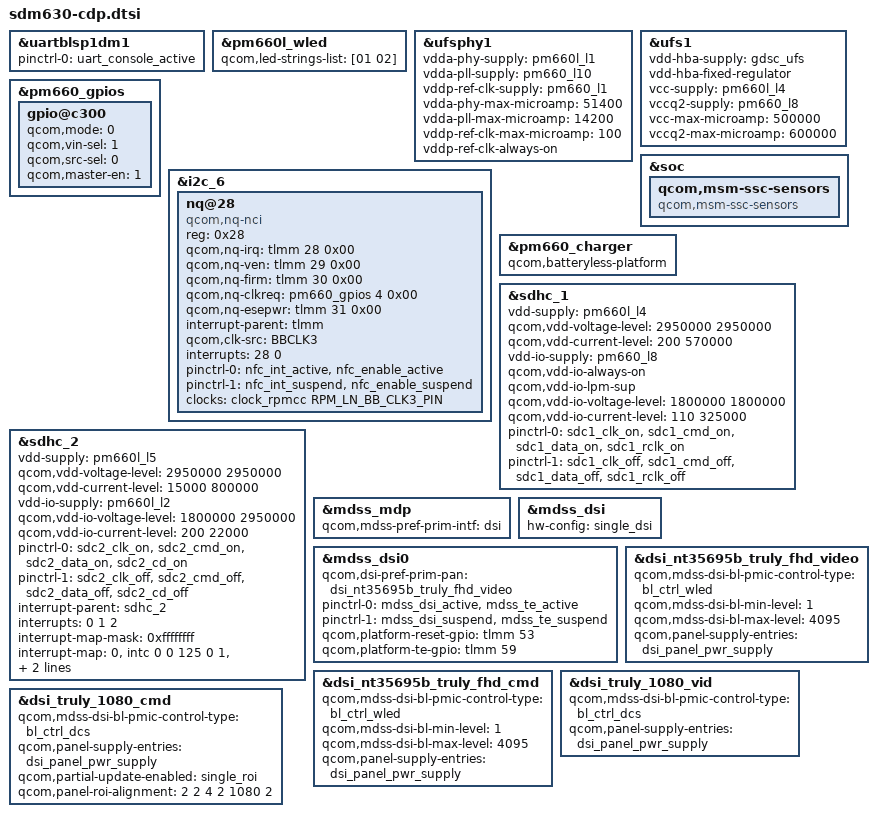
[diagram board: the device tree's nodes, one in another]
/* Copyright (c) 2017, The Linux Foundation. All rights reserved.
 *
 * This program is free software; you can redistribute it and/or modify
 * it under the terms of the GNU General Public License version 2 and
 * only version 2 as published by the Free Software Foundation.
 *
 * This program is distributed in the hope that it will be useful,
 * but WITHOUT ANY WARRANTY; without even the implied warranty of
 * MERCHANTABILITY or FITNESS FOR A PARTICULAR PURPOSE.  See the
 * GNU General Public License for more details.
 */

#include "sdm660-pinctrl.dtsi"
#include "sdm630-camera-sensor-cdp.dtsi"
/ {
};

&uartblsp1dm1 {
	status = "ok";
	pinctrl-names = "default";
	pinctrl-0 = <&uart_console_active>;
};

&pm660l_wled {
	qcom,led-strings-list = [01 02];
};

&ufsphy1 {
	vdda-phy-supply = <&pm660l_l1>;
	vdda-pll-supply = <&pm660_l10>;
	vddp-ref-clk-supply = <&pm660_l1>;
	vdda-phy-max-microamp = <51400>;
	vdda-pll-max-microamp = <14200>;
	vddp-ref-clk-max-microamp = <100>;
	vddp-ref-clk-always-on;
	status = "ok";
};

&ufs1 {
	vdd-hba-supply = <&gdsc_ufs>;
	vdd-hba-fixed-regulator;
	vcc-supply = <&pm660l_l4>;
	vccq2-supply = <&pm660_l8>;
	vcc-max-microamp = <500000>;
	vccq2-max-microamp = <600000>;
	status = "ok";
};

&pm660_gpios {
	/* GPIO 4 (NFC_CLK_REQ) */
	gpio@c300 {
		qcom,mode = <0>;
		qcom,vin-sel = <1>;
		qcom,src-sel = <0>;
		qcom,master-en = <1>;
		status = "okay";
	};
};

&i2c_6 { /* BLSP1 QUP6 (NFC) */
	status = "okay";
	nq@28 {
		compatible = "qcom,nq-nci";
		reg = <0x28>;
		qcom,nq-irq = <&tlmm 28 0x00>;
		qcom,nq-ven = <&tlmm 29 0x00>;
		qcom,nq-firm = <&tlmm 30 0x00>;
		qcom,nq-clkreq = <&pm660_gpios 4 0x00>;
		qcom,nq-esepwr = <&tlmm 31 0x00>;
		interrupt-parent = <&tlmm>;
		qcom,clk-src = "BBCLK3";
		interrupts = <28 0>;
		interrupt-names = "nfc_irq";
		pinctrl-names = "nfc_active", "nfc_suspend";
		pinctrl-0 = <&nfc_int_active &nfc_enable_active>;
		pinctrl-1 = <&nfc_int_suspend &nfc_enable_suspend>;
		clocks = <&clock_rpmcc RPM_LN_BB_CLK3_PIN>;
		clock-names = "ref_clk";
	};
};
&soc {
	qcom,msm-ssc-sensors {
		compatible = "qcom,msm-ssc-sensors";
	};
};

&pm660_charger {
	qcom,batteryless-platform;
};

&sdhc_1 {
	/* device core power supply */
	vdd-supply = <&pm660l_l4>;
	qcom,vdd-voltage-level = <2950000 2950000>;
	qcom,vdd-current-level = <200 570000>;

	/* device communication power supply */
	vdd-io-supply = <&pm660_l8>;
	qcom,vdd-io-always-on;
	qcom,vdd-io-lpm-sup;
	qcom,vdd-io-voltage-level = <1800000 1800000>;
	qcom,vdd-io-current-level = <110 325000>;

	pinctrl-names = "active", "sleep";
	pinctrl-0 = <&sdc1_clk_on &sdc1_cmd_on &sdc1_data_on &sdc1_rclk_on>;
	pinctrl-1 = <&sdc1_clk_off &sdc1_cmd_off &sdc1_data_off &sdc1_rclk_off>;

	status = "ok";
};

&sdhc_2 {
	/* device core power supply */
	vdd-supply = <&pm660l_l5>;
	qcom,vdd-voltage-level = <2950000 2950000>;
	qcom,vdd-current-level = <15000 800000>;

	/* device communication power supply */
	vdd-io-supply = <&pm660l_l2>;
	qcom,vdd-io-voltage-level = <1800000 2950000>;
	qcom,vdd-io-current-level = <200 22000>;

	pinctrl-names = "active", "sleep";
	pinctrl-0 = <&sdc2_clk_on &sdc2_cmd_on &sdc2_data_on &sdc2_cd_on>;
	pinctrl-1 = <&sdc2_clk_off &sdc2_cmd_off &sdc2_data_off &sdc2_cd_off>;

	#address-cells = <0>;
	interrupt-parent = <&sdhc_2>;
	interrupts = <0 1 2>;
	#interrupt-cells = <1>;
	interrupt-map-mask = <0xffffffff>;
	interrupt-map = <0 &intc 0 0 125 0
			1 &intc 0 0 221 0
			2 &tlmm 54 0>;
	interrupt-names = "hc_irq", "pwr_irq", "status_irq";
	cd-gpios = <&tlmm 54 0x1>;

	status = "ok";
};

&mdss_mdp {
	qcom,mdss-pref-prim-intf = "dsi";
};

&mdss_dsi {
	hw-config = "single_dsi";
};

&mdss_dsi0 {
	qcom,dsi-pref-prim-pan = <&dsi_nt35695b_truly_fhd_video>;
	pinctrl-names = "mdss_default", "mdss_sleep";
	pinctrl-0 = <&mdss_dsi_active &mdss_te_active>;
	pinctrl-1 = <&mdss_dsi_suspend &mdss_te_suspend>;
	qcom,platform-reset-gpio = <&tlmm 53 0>;
	qcom,platform-te-gpio = <&tlmm 59 0>;
};

&pm660l_wled {
	qcom,led-strings-list = [01 02];
};

&dsi_nt35695b_truly_fhd_video {
	qcom,mdss-dsi-bl-pmic-control-type = "bl_ctrl_wled";
	qcom,mdss-dsi-bl-min-level = <1>;
	qcom,mdss-dsi-bl-max-level = <4095>;
	qcom,panel-supply-entries = <&dsi_panel_pwr_supply>;
};

&dsi_nt35695b_truly_fhd_cmd {
	qcom,mdss-dsi-bl-pmic-control-type = "bl_ctrl_wled";
	qcom,mdss-dsi-bl-min-level = <1>;
	qcom,mdss-dsi-bl-max-level = <4095>;
	qcom,panel-supply-entries = <&dsi_panel_pwr_supply>;
};

&dsi_truly_1080_vid {
	qcom,mdss-dsi-bl-pmic-control-type = "bl_ctrl_dcs";
	qcom,panel-supply-entries = <&dsi_panel_pwr_supply>;
};

&dsi_truly_1080_cmd {
	qcom,mdss-dsi-bl-pmic-control-type = "bl_ctrl_dcs";
	qcom,panel-supply-entries = <&dsi_panel_pwr_supply>;
	qcom,partial-update-enabled = "single_roi";
	qcom,panel-roi-alignment = <2 2 4 2 1080 2>;
};
